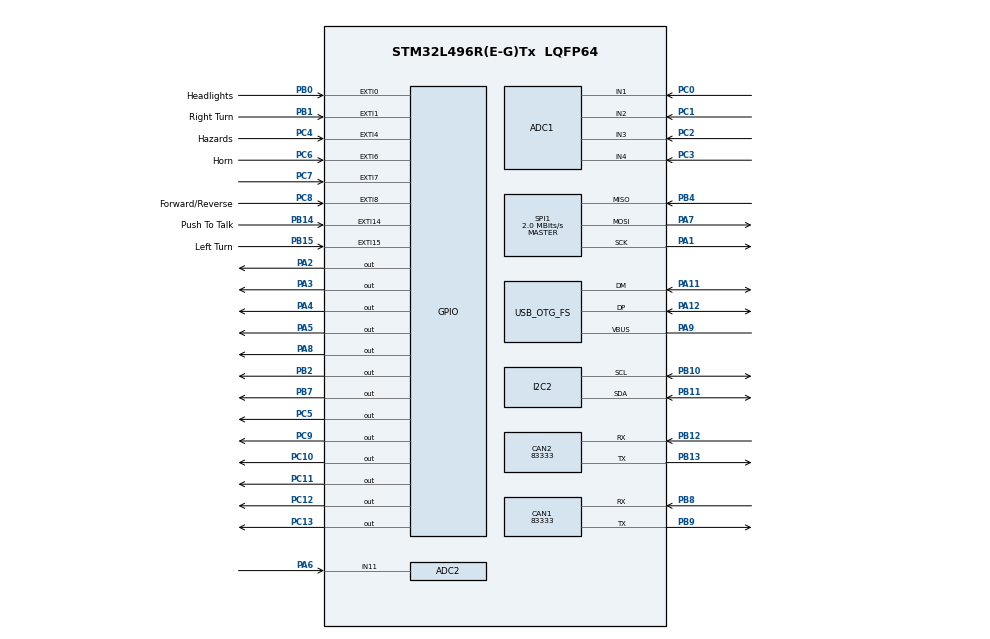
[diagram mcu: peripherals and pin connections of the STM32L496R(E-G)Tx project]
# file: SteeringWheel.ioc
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ADC1.Channel-0\#ChannelRegularConversion=ADC_CHANNEL_1
ADC1.NbrOfConversionFlag=1
ADC1.OffsetNumber-0\#ChannelRegularConversion=ADC_OFFSET_NONE
ADC1.Rank-0\#ChannelRegularConversion=1
ADC1.SamplingTime-0\#ChannelRegularConversion=ADC_SAMPLETIME_2CYCLES_5
ADC1.master=1
ADC2.Channel-1\#ChannelRegularConversion=ADC_CHANNEL_11
ADC2.NbrOfConversionFlag=1
ADC2.OffsetNumber-1\#ChannelRegularConversion=ADC_OFFSET_NONE
ADC2.Rank-1\#ChannelRegularConversion=1
ADC2.SamplingTime-1\#ChannelRegularConversion=ADC_SAMPLETIME_2CYCLES_5
CAN1.CalculateBaudRate=83333
CAN1.CalculateTimeBit=12000
CAN1.CalculateTimeQuantum=4000.0
CAN2.CalculateBaudRate=83333
CAN2.CalculateTimeBit=12000
CAN2.CalculateTimeQuantum=4000.0
Mcu.Family=STM32L4
Mcu.Name=STM32L496R(E-G)Tx
Mcu.Package=LQFP64
NVIC.PriorityGroup=NVIC_PRIORITYGROUP_4
PA1.Mode=Full_Duplex_Master
PA1.Signal=SPI1_SCK
PA11.Mode=Device_Only
PA11.Signal=USB_OTG_FS_DM
PA12.Mode=Device_Only
PA12.Signal=USB_OTG_FS_DP
PA13\ (JTMS/SWDIO).Mode=Trace_Asynchronous_SW
PA13\ (JTMS/SWDIO).Signal=SYS_JTMS-SWDIO
PA14\ (JTCK/SWCLK).Mode=Trace_Asynchronous_SW
PA14\ (JTCK/SWCLK).Signal=SYS_JTCK-SWCLK
PA2.Signal=GPIO_Output
PA3.Signal=GPIO_Output
PA4.Signal=GPIO_Output
PA5.Signal=GPIO_Output
PA6.Signal=ADCx_IN11
PA7.Mode=Full_Duplex_Master
PA7.Signal=SPI1_MOSI
PA8.Signal=GPIO_Output
PA9.Mode=Activate_VBUS
PA9.Signal=USB_OTG_FS_VBUS
PB0.GPIO_Label=Headlights
PB0.Signal=GPXTI0
PB1.GPIO_Label=Right Turn
PB1.Signal=GPXTI1
PB10.Mode=I2C
PB10.Signal=I2C2_SCL
PB11.Mode=I2C
PB11.Signal=I2C2_SDA
PB12.Mode=CAN_Activate
PB12.Signal=CAN2_RX
PB13.Mode=CAN_Activate
PB13.Signal=CAN2_TX
PB14.GPIO_Label=Push To Talk
PB14.Signal=GPXTI14
PB15.GPIO_Label=Left Turn
PB15.Signal=GPXTI15
PB2.Signal=GPIO_Output
PB3\ (JTDO/TRACESWO).Mode=Trace_Asynchronous_SW
PB3\ (JTDO/TRACESWO).Signal=SYS_JTDO-SWO
PB4\ (NJTRST).Mode=Full_Duplex_Master
PB4\ (NJTRST).Signal=SPI1_MISO
PB7.Signal=GPIO_Output
PB8.Mode=CAN_Activate
PB8.Signal=CAN1_RX
PB9.Mode=CAN_Activate
PB9.Signal=CAN1_TX
PC0.Signal=ADCx_IN1
PC1.Signal=ADCx_IN2
PC10.Signal=GPIO_Output
PC11.Signal=GPIO_Output
PC12.Signal=GPIO_Output
PC13.Signal=GPIO_Output
PC2.Signal=ADCx_IN3
PC3.Signal=ADCx_IN4
PC4.GPIO_Label=Hazards
PC4.Signal=GPXTI4
PC5.Signal=GPIO_Output
PC6.GPIO_Label=Horn
PC6.Signal=GPXTI6
PC7.Signal=GPXTI7
PC8.GPIO_Label=Forward/Reverse
PC8.Signal=GPXTI8
PC9.Signal=GPIO_Output
ProjectManager.HeapSize=0x200
ProjectManager.StackSize=0x400
ProjectManager.TargetToolchain=STM32CubeIDE
RCC.HSE_VALUE=8000000
RCC.HSI48_VALUE=48000000
RCC.HSI_VALUE=16000000
RCC.LSE_VALUE=32768
RCC.MSI_VALUE=4000000
RCC.VCOOutputFreq_Value=32000000
SH.ADCx_IN1.0=ADC1_IN1,IN1-Single-Ended
SH.ADCx_IN11.0=ADC2_IN11,IN11-Single-Ended
SH.ADCx_IN2.0=ADC1_IN2,IN2-Single-Ended
SH.ADCx_IN3.0=ADC1_IN3,IN3-Single-Ended
SH.ADCx_IN4.0=ADC1_IN4,IN4-Single-Ended
SPI1.CalculateBaudRate=2.0 MBits/s
SPI1.Direction=SPI_DIRECTION_2LINES
SPI1.Mode=SPI_MODE_MASTER
SPI1.VirtualType=VM_MASTER
USB_OTG_FS.VirtualMode=Device_Only
board=custom

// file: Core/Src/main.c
/* USER CODE BEGIN Header */
/**
  ******************************************************************************
  * @file           : main.c
  * @brief          : Main program body
  ******************************************************************************
  * @attention
  *
  * Copyright (c) 2023 STMicroelectronics.
  * All rights reserved.
  *
  * This software is licensed under terms that can be found in the LICENSE file
  * in the root directory of this software component.
  * If no LICENSE file comes with this software, it is provided AS-IS.
  *
  ******************************************************************************
  */
/* USER CODE END Header */
#include "main.h"

/* USER CODE BEGIN Includes */
#include "pots_avg.c"
#include <string.h>
#include <stdio.h>
/* USER CODE END Includes */

ADC_HandleTypeDef hadc1;
ADC_HandleTypeDef hadc2;

CAN_HandleTypeDef hcan1;
CAN_HandleTypeDef hcan2;

I2C_HandleTypeDef hi2c2;

SPI_HandleTypeDef hspi1;

PCD_HandleTypeDef hpcd_USB_OTG_FS;

void SystemClock_Config(void);
void PeriphCommonClock_Config(void);
static void MX_GPIO_Init(void);
static void MX_ADC1_Init(void);
static void MX_CAN1_Init(void);
static void MX_CAN2_Init(void);
static void MX_I2C2_Init(void);
static void MX_SPI1_Init(void);
static void MX_USB_OTG_FS_PCD_Init(void);
static void MX_ADC2_Init(void);

int main(void)
{
  /* USER CODE BEGIN 1 */
  uint16_t raw1, raw2, raw3, raw4, raw5, raw6, result1, result2;
  char msg[10];
  /* USER CODE END 1 */

  /* MCU Configuration--------------------------------------------------------*/

  /* Reset of all peripherals, Initializes the Flash interface and the Systick. */
  HAL_Init();

  /* Configure the system clock */
  SystemClock_Config();

/* Configure the peripherals common clocks */
  PeriphCommonClock_Config();

  /* Initialize all configured peripherals */
  MX_GPIO_Init();
  MX_ADC1_Init();
  MX_CAN1_Init();
  MX_CAN2_Init();
  MX_I2C2_Init();
  MX_SPI1_Init();
  MX_USB_OTG_FS_PCD_Init();
  MX_ADC2_Init();

  /* Infinite loop */
  while (1)
  {

	  // Get all ADCs value
	  HAL_ADC_Start(&hadc1);
	  HAL_ADC_PollForConversion(&hadc1, HAL_MAX_DELAY);
	  raw1 = HAL_ADC_GetValue(&hadc1);

	  HAL_ADC_Start(&hadc2);
	  HAL_ADC_PollForConversion(&hadc2, HAL_MAX_DELAY);
	  raw2 = HAL_ADC_GetValue(&hadc2);

	  //	  HAL_ADC_Start(&hadc3);
	  //	  HAL_ADC_PollForConversion(&hadc3, HAL_MAX_DELAY);
	  //	  raw3 = HAL_ADC_GetValue(&hadc3);
	  //
	  //	  HAL_ADC_Start(&hadc4);
	  //	  HAL_ADC_PollForConversion(&hadc4, HAL_MAX_DELAY);
	  //	  raw4 = HAL_ADC_GetValue(&hadc4);

	  //	  HAL_ADC_Start(&hadc5);
	  //	  HAL_ADC_PollForConversion(&hadc5, HAL_MAX_DELAY);
	  //	  raw5 = HAL_ADC_GetValue(&hadc5);
	  //
	  //	  HAL_ADC_Start(&hadc6);
	  //	  HAL_ADC_PollForConversion(&hadc6, HAL_MAX_DELAY);
	  //	  raw6 = HAL_ADC_GetValue(&hadc6);

	  //	  result1 = Median(raw1, raw2, raw3);
	  //	  result2 = Median(raw4, raw5, raw6);

	  // Convert to string and print
	  sprintf(msg, "%hu\r\n", raw1);
	  HAL_UART_Transmit(&huart2, (uint8_t*)msg, strlen(msg), HAL_MAX_DELAY);

	  sprintf(msg, "%hu\r\n", raw2);
	  HAL_UART_Transmit(&huart2, (uint8_t*)msg, strlen(msg), HAL_MAX_DELAY);

	  // Delay
	  HAL_Delay(1);
  }
}

void SystemClock_Config(void)
{
  RCC_OscInitTypeDef RCC_OscInitStruct = {0};
  RCC_ClkInitTypeDef RCC_ClkInitStruct = {0};

  /** Configure the main internal regulator output voltage
  */
  if (HAL_PWREx_ControlVoltageScaling(PWR_REGULATOR_VOLTAGE_SCALE1) != HAL_OK)
  {
    Error_Handler();
  }

  /** Initializes the RCC Oscillators according to the specified parameters
  * in the RCC_OscInitTypeDef structure.
  */
  RCC_OscInitStruct.OscillatorType = RCC_OSCILLATORTYPE_LSE|RCC_OSCILLATORTYPE_MSI;
  RCC_OscInitStruct.LSEState = RCC_LSE_OFF;
  RCC_OscInitStruct.MSIState = RCC_MSI_ON;
  RCC_OscInitStruct.MSICalibrationValue = 0;
  RCC_OscInitStruct.MSIClockRange = RCC_MSIRANGE_6;
  RCC_OscInitStruct.PLL.PLLState = RCC_PLL_NONE;
  if (HAL_RCC_OscConfig(&RCC_OscInitStruct) != HAL_OK)
  {
    Error_Handler();
  }

  /** Initializes the CPU, AHB and APB buses clocks
  */
  RCC_ClkInitStruct.ClockType = RCC_CLOCKTYPE_HCLK|RCC_CLOCKTYPE_SYSCLK
                              |RCC_CLOCKTYPE_PCLK1|RCC_CLOCKTYPE_PCLK2;
  RCC_ClkInitStruct.SYSCLKSource = RCC_SYSCLKSOURCE_MSI;
  RCC_ClkInitStruct.AHBCLKDivider = RCC_SYSCLK_DIV1;
  RCC_ClkInitStruct.APB1CLKDivider = RCC_HCLK_DIV1;
  RCC_ClkInitStruct.APB2CLKDivider = RCC_HCLK_DIV1;

  if (HAL_RCC_ClockConfig(&RCC_ClkInitStruct, FLASH_LATENCY_0) != HAL_OK)
  {
    Error_Handler();
  }

  /** Enable MSI Auto calibration
  */
  HAL_RCCEx_EnableMSIPLLMode();
}

void PeriphCommonClock_Config(void)
{
  RCC_PeriphCLKInitTypeDef PeriphClkInit = {0};

  /** Initializes the peripherals clock
  */
  PeriphClkInit.PeriphClockSelection = RCC_PERIPHCLK_USB|RCC_PERIPHCLK_ADC;
  PeriphClkInit.AdcClockSelection = RCC_ADCCLKSOURCE_PLLSAI1;
  PeriphClkInit.UsbClockSelection = RCC_USBCLKSOURCE_PLLSAI1;
  PeriphClkInit.PLLSAI1.PLLSAI1Source = RCC_PLLSOURCE_MSI;
  PeriphClkInit.PLLSAI1.PLLSAI1M = 1;
  PeriphClkInit.PLLSAI1.PLLSAI1N = 8;
  PeriphClkInit.PLLSAI1.PLLSAI1P = RCC_PLLP_DIV2;
  PeriphClkInit.PLLSAI1.PLLSAI1Q = RCC_PLLQ_DIV2;
  PeriphClkInit.PLLSAI1.PLLSAI1R = RCC_PLLR_DIV2;
  PeriphClkInit.PLLSAI1.PLLSAI1ClockOut = RCC_PLLSAI1_48M2CLK|RCC_PLLSAI1_ADC1CLK;
  if (HAL_RCCEx_PeriphCLKConfig(&PeriphClkInit) != HAL_OK)
  {
    Error_Handler();
  }
}

static void MX_ADC1_Init(void)
{

  ADC_MultiModeTypeDef multimode = {0};
  ADC_ChannelConfTypeDef sConfig = {0};

  /** Common config
  */
  hadc1.Instance = ADC1;
  hadc1.Init.ClockPrescaler = ADC_CLOCK_ASYNC_DIV1;
  hadc1.Init.Resolution = ADC_RESOLUTION_12B;
  hadc1.Init.DataAlign = ADC_DATAALIGN_RIGHT;
  hadc1.Init.ScanConvMode = ADC_SCAN_DISABLE;
  hadc1.Init.EOCSelection = ADC_EOC_SINGLE_CONV;
  hadc1.Init.LowPowerAutoWait = DISABLE;
  hadc1.Init.ContinuousConvMode = DISABLE;
  hadc1.Init.NbrOfConversion = 1;
  hadc1.Init.DiscontinuousConvMode = DISABLE;
  hadc1.Init.ExternalTrigConv = ADC_SOFTWARE_START;
  hadc1.Init.ExternalTrigConvEdge = ADC_EXTERNALTRIGCONVEDGE_NONE;
  hadc1.Init.DMAContinuousRequests = DISABLE;
  hadc1.Init.Overrun = ADC_OVR_DATA_PRESERVED;
  hadc1.Init.OversamplingMode = DISABLE;
  if (HAL_ADC_Init(&hadc1) != HAL_OK)
  {
    Error_Handler();
  }

  /** Configure the ADC multi-mode
  */
  multimode.Mode = ADC_MODE_INDEPENDENT;
  if (HAL_ADCEx_MultiModeConfigChannel(&hadc1, &multimode) != HAL_OK)
  {
    Error_Handler();
  }

  /** Configure Regular Channel
  */
  sConfig.Channel = ADC_CHANNEL_1;
  sConfig.Rank = ADC_REGULAR_RANK_1;
  sConfig.SamplingTime = ADC_SAMPLETIME_2CYCLES_5;
  sConfig.SingleDiff = ADC_SINGLE_ENDED;
  sConfig.OffsetNumber = ADC_OFFSET_NONE;
  sConfig.Offset = 0;
  if (HAL_ADC_ConfigChannel(&hadc1, &sConfig) != HAL_OK)
  {
    Error_Handler();
  }

}

static void MX_ADC2_Init(void)
{

  ADC_ChannelConfTypeDef sConfig = {0};

  /** Common config
  */
  hadc2.Instance = ADC2;
  hadc2.Init.ClockPrescaler = ADC_CLOCK_ASYNC_DIV1;
  hadc2.Init.Resolution = ADC_RESOLUTION_12B;
  hadc2.Init.DataAlign = ADC_DATAALIGN_RIGHT;
  hadc2.Init.ScanConvMode = ADC_SCAN_DISABLE;
  hadc2.Init.EOCSelection = ADC_EOC_SINGLE_CONV;
  hadc2.Init.LowPowerAutoWait = DISABLE;
  hadc2.Init.ContinuousConvMode = DISABLE;
  hadc2.Init.NbrOfConversion = 1;
  hadc2.Init.DiscontinuousConvMode = DISABLE;
  hadc2.Init.ExternalTrigConv = ADC_SOFTWARE_START;
  hadc2.Init.ExternalTrigConvEdge = ADC_EXTERNALTRIGCONVEDGE_NONE;
  hadc2.Init.DMAContinuousRequests = DISABLE;
  hadc2.Init.Overrun = ADC_OVR_DATA_PRESERVED;
  hadc2.Init.OversamplingMode = DISABLE;
  if (HAL_ADC_Init(&hadc2) != HAL_OK)
  {
    Error_Handler();
  }

  /** Configure Regular Channel
  */
  sConfig.Channel = ADC_CHANNEL_11;
  sConfig.Rank = ADC_REGULAR_RANK_1;
  sConfig.SamplingTime = ADC_SAMPLETIME_2CYCLES_5;
  sConfig.SingleDiff = ADC_SINGLE_ENDED;
  sConfig.OffsetNumber = ADC_OFFSET_NONE;
  sConfig.Offset = 0;
  if (HAL_ADC_ConfigChannel(&hadc2, &sConfig) != HAL_OK)
  {
    Error_Handler();
  }

}

static void MX_CAN1_Init(void)
{

  hcan1.Instance = CAN1;
  hcan1.Init.Prescaler = 16;
  hcan1.Init.Mode = CAN_MODE_NORMAL;
  hcan1.Init.SyncJumpWidth = CAN_SJW_1TQ;
  hcan1.Init.TimeSeg1 = CAN_BS1_1TQ;
  hcan1.Init.TimeSeg2 = CAN_BS2_1TQ;
  hcan1.Init.TimeTriggeredMode = DISABLE;
  hcan1.Init.AutoBusOff = DISABLE;
  hcan1.Init.AutoWakeUp = DISABLE;
  hcan1.Init.AutoRetransmission = DISABLE;
  hcan1.Init.ReceiveFifoLocked = DISABLE;
  hcan1.Init.TransmitFifoPriority = DISABLE;
  if (HAL_CAN_Init(&hcan1) != HAL_OK)
  {
    Error_Handler();
  }

}

static void MX_CAN2_Init(void)
{

  hcan2.Instance = CAN2;
  hcan2.Init.Prescaler = 16;
  hcan2.Init.Mode = CAN_MODE_NORMAL;
  hcan2.Init.SyncJumpWidth = CAN_SJW_1TQ;
  hcan2.Init.TimeSeg1 = CAN_BS1_1TQ;
  hcan2.Init.TimeSeg2 = CAN_BS2_1TQ;
  hcan2.Init.TimeTriggeredMode = DISABLE;
  hcan2.Init.AutoBusOff = DISABLE;
  hcan2.Init.AutoWakeUp = DISABLE;
  hcan2.Init.AutoRetransmission = DISABLE;
  hcan2.Init.ReceiveFifoLocked = DISABLE;
  hcan2.Init.TransmitFifoPriority = DISABLE;
  if (HAL_CAN_Init(&hcan2) != HAL_OK)
  {
    Error_Handler();
  }

}

static void MX_I2C2_Init(void)
{

  hi2c2.Instance = I2C2;
  hi2c2.Init.Timing = 0x00000E14;
  hi2c2.Init.OwnAddress1 = 0;
  hi2c2.Init.AddressingMode = I2C_ADDRESSINGMODE_7BIT;
  hi2c2.Init.DualAddressMode = I2C_DUALADDRESS_DISABLE;
  hi2c2.Init.OwnAddress2 = 0;
  hi2c2.Init.OwnAddress2Masks = I2C_OA2_NOMASK;
  hi2c2.Init.GeneralCallMode = I2C_GENERALCALL_DISABLE;
  hi2c2.Init.NoStretchMode = I2C_NOSTRETCH_DISABLE;
  if (HAL_I2C_Init(&hi2c2) != HAL_OK)
  {
    Error_Handler();
  }

  /** Configure Analogue filter
  */
  if (HAL_I2CEx_ConfigAnalogFilter(&hi2c2, I2C_ANALOGFILTER_ENABLE) != HAL_OK)
  {
    Error_Handler();
  }

  /** Configure Digital filter
  */
  if (HAL_I2CEx_ConfigDigitalFilter(&hi2c2, 0) != HAL_OK)
  {
    Error_Handler();
  }

}

static void MX_SPI1_Init(void)
{

  /* SPI1 parameter configuration*/
  hspi1.Instance = SPI1;
  hspi1.Init.Mode = SPI_MODE_MASTER;
  hspi1.Init.Direction = SPI_DIRECTION_2LINES;
  hspi1.Init.DataSize = SPI_DATASIZE_4BIT;
  hspi1.Init.CLKPolarity = SPI_POLARITY_LOW;
  hspi1.Init.CLKPhase = SPI_PHASE_1EDGE;
  hspi1.Init.NSS = SPI_NSS_SOFT;
  hspi1.Init.BaudRatePrescaler = SPI_BAUDRATEPRESCALER_2;
  hspi1.Init.FirstBit = SPI_FIRSTBIT_MSB;
  hspi1.Init.TIMode = SPI_TIMODE_DISABLE;
  hspi1.Init.CRCCalculation = SPI_CRCCALCULATION_DISABLE;
  hspi1.Init.CRCPolynomial = 7;
  hspi1.Init.CRCLength = SPI_CRC_LENGTH_DATASIZE;
  hspi1.Init.NSSPMode = SPI_NSS_PULSE_ENABLE;
  if (HAL_SPI_Init(&hspi1) != HAL_OK)
  {
    Error_Handler();
  }

}

static void MX_USB_OTG_FS_PCD_Init(void)
{

  hpcd_USB_OTG_FS.Instance = USB_OTG_FS;
  hpcd_USB_OTG_FS.Init.dev_endpoints = 6;
  hpcd_USB_OTG_FS.Init.speed = PCD_SPEED_FULL;
  hpcd_USB_OTG_FS.Init.phy_itface = PCD_PHY_EMBEDDED;
  hpcd_USB_OTG_FS.Init.Sof_enable = DISABLE;
  hpcd_USB_OTG_FS.Init.low_power_enable = DISABLE;
  hpcd_USB_OTG_FS.Init.lpm_enable = DISABLE;
  hpcd_USB_OTG_FS.Init.battery_charging_enable = ENABLE;
  hpcd_USB_OTG_FS.Init.use_dedicated_ep1 = DISABLE;
  hpcd_USB_OTG_FS.Init.vbus_sensing_enable = ENABLE;
  if (HAL_PCD_Init(&hpcd_USB_OTG_FS) != HAL_OK)
  {
    Error_Handler();
  }

}

static void MX_GPIO_Init(void)
{
  GPIO_InitTypeDef GPIO_InitStruct = {0};

  /* GPIO Ports Clock Enable */
  __HAL_RCC_GPIOC_CLK_ENABLE();
  __HAL_RCC_GPIOA_CLK_ENABLE();
  __HAL_RCC_GPIOB_CLK_ENABLE();

  /*Configure GPIO pin Output Level */
  HAL_GPIO_WritePin(GPIOC, GPIO_PIN_13|GPIO_PIN_5|GPIO_PIN_9|GPIO_PIN_10
                          |GPIO_PIN_11|GPIO_PIN_12, GPIO_PIN_RESET);

  /*Configure GPIO pin Output Level */
  HAL_GPIO_WritePin(GPIOA, GPIO_PIN_2|GPIO_PIN_3|GPIO_PIN_4|GPIO_PIN_5
                          |GPIO_PIN_8, GPIO_PIN_RESET);

  /*Configure GPIO pin Output Level */
  HAL_GPIO_WritePin(GPIOB, GPIO_PIN_2|GPIO_PIN_7, GPIO_PIN_RESET);

  /*Configure GPIO pins : PC13 PC5 PC9 PC10
                           PC11 PC12 */
  GPIO_InitStruct.Pin = GPIO_PIN_13|GPIO_PIN_5|GPIO_PIN_9|GPIO_PIN_10
                          |GPIO_PIN_11|GPIO_PIN_12;
  GPIO_InitStruct.Mode = GPIO_MODE_OUTPUT_PP;
  GPIO_InitStruct.Pull = GPIO_NOPULL;
  GPIO_InitStruct.Speed = GPIO_SPEED_FREQ_LOW;
  HAL_GPIO_Init(GPIOC, &GPIO_InitStruct);

  /*Configure GPIO pins : PA2 PA3 PA4 PA5
                           PA8 */
  GPIO_InitStruct.Pin = GPIO_PIN_2|GPIO_PIN_3|GPIO_PIN_4|GPIO_PIN_5
                          |GPIO_PIN_8;
  GPIO_InitStruct.Mode = GPIO_MODE_OUTPUT_PP;
  GPIO_InitStruct.Pull = GPIO_NOPULL;
  GPIO_InitStruct.Speed = GPIO_SPEED_FREQ_LOW;
  HAL_GPIO_Init(GPIOA, &GPIO_InitStruct);

  /*Configure GPIO pins : Hazards_Pin Horn_Pin PC7 Forward_Reverse_Pin */
  GPIO_InitStruct.Pin = Hazards_Pin|Horn_Pin|GPIO_PIN_7|Forward_Reverse_Pin;
  GPIO_InitStruct.Mode = GPIO_MODE_IT_RISING;
  GPIO_InitStruct.Pull = GPIO_NOPULL;
  HAL_GPIO_Init(GPIOC, &GPIO_InitStruct);

  /*Configure GPIO pins : Headlights_Pin Right_Turn_Pin Push_To_Talk_Pin Left_Turn_Pin */
  GPIO_InitStruct.Pin = Headlights_Pin|Right_Turn_Pin|Push_To_Talk_Pin|Left_Turn_Pin;
  GPIO_InitStruct.Mode = GPIO_MODE_IT_RISING;
  GPIO_InitStruct.Pull = GPIO_NOPULL;
  HAL_GPIO_Init(GPIOB, &GPIO_InitStruct);

  /*Configure GPIO pins : PB2 PB7 */
  GPIO_InitStruct.Pin = GPIO_PIN_2|GPIO_PIN_7;
  GPIO_InitStruct.Mode = GPIO_MODE_OUTPUT_PP;
  GPIO_InitStruct.Pull = GPIO_NOPULL;
  GPIO_InitStruct.Speed = GPIO_SPEED_FREQ_LOW;
  HAL_GPIO_Init(GPIOB, &GPIO_InitStruct);

}

/* USER CODE BEGIN 4 */
void HAL_GPIO_EXTI_Callback(uint16_t GPIO_Pin)
 {
	 if(GPIO_Pin== GPIO_PIN_4)
	 {
		 // Push to Talk
	 }
	 else if(GPIO_Pin== GPIO_PIN_6)
	 {
	 		 // Horn
	 }
	 else if(GPIO_Pin== GPIO_PIN_7)
	 {

	 }
	 else if(GPIO_Pin== GPIO_PIN_8)
	 {
	 		 // Forward/Reverse
	 }
	 else if(GPIO_Pin== GPIO_PIN_0)
	 {
	 		 // Head lights
	 }
	 else if(GPIO_Pin== GPIO_PIN_1)
	 {
	 		 // Right Turn
	 }
	 else if(GPIO_Pin== GPIO_PIN_14)
	 {
	 		 // Hazards
	 }
	 else if(GPIO_Pin== GPIO_PIN_15)
	 {
		 // Left Turn
	 }

 }
/* USER CODE END 4 */

void Error_Handler(void)
{
  __disable_irq();
  while (1)
  {
  }
}
